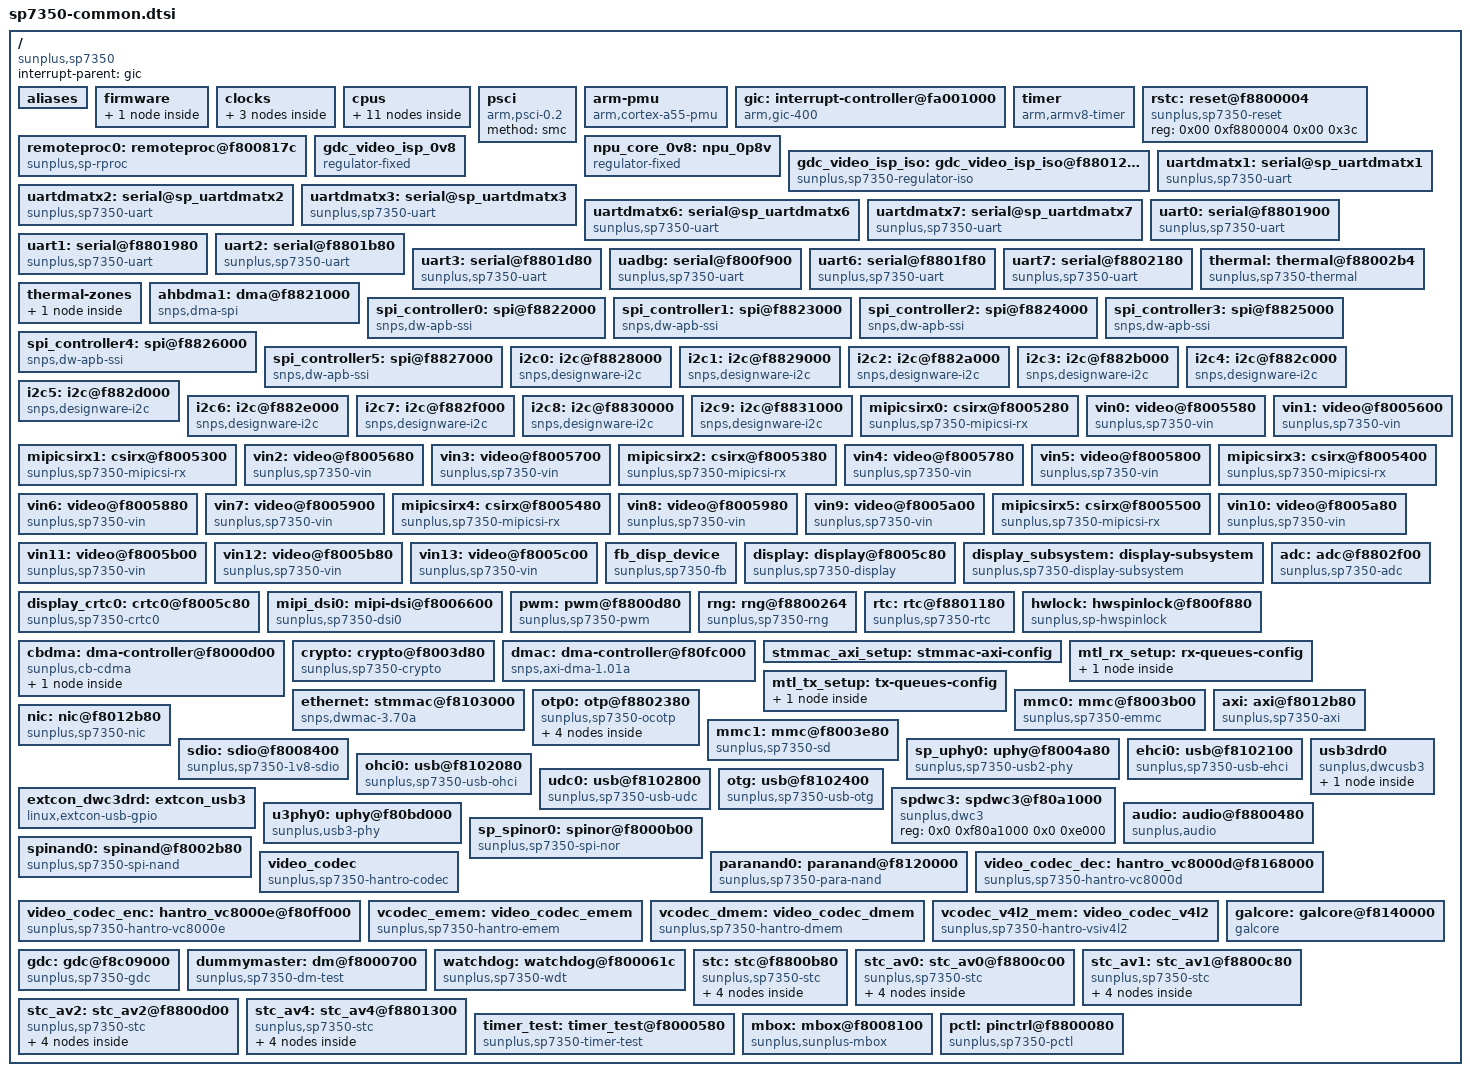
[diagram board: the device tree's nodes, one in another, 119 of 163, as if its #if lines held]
// SPDX-License-Identifier: (GPL-2.0 OR MIT)

/dts-v1/;

#include <autoconf.h>
#include <dt-bindings/interrupt-controller/irq.h>
#include <dt-bindings/interrupt-controller/arm-gic.h>
#include <dt-bindings/gpio/gpio.h>
#include <dt-bindings/clock/sp-sp7350.h>
#include <dt-bindings/reset/sp-sp7350.h>
#include <dt-bindings/pinctrl/sppctl-sp7350.h>
#include <dt-bindings/regulator/sunplus,sp7350-iso.h>

/ {
	compatible = "sunplus,sp7350";
	interrupt-parent = <&gic>;
	#address-cells = <2>;
	#size-cells = <2>;

	aliases {
#ifdef ENABLE_DMATX1
		serial21 = &uartdmatx1;
#endif
#ifdef ENABLE_DMATX2
		serial22 = &uartdmatx2;
#endif
#ifdef ENABLE_DMATX3
		serial23 = &uartdmatx3;
#endif
#ifdef ENABLE_DMATX6
		serial26 = &uartdmatx6;
#endif
#ifdef ENABLE_DMATX7
		serial27 = &uartdmatx7;
#endif
		serial0 = &uart0;
		serial1 = &uart1;
		serial2 = &uart2;
		serial3 = &uart3;
		serial5 = &uadbg;
		serial6 = &uart6;
		serial7 = &uart7;

		i2cno0 = &i2c0;
		i2cno1 = &i2c1;
		i2cno2 = &i2c2;
		i2cno3 = &i2c3;
		i2cno4 = &i2c4;
		i2cno5 = &i2c5;
		i2cno6 = &i2c6;
		i2cno7 = &i2c7;
		i2cno8 = &i2c8;
		i2cno9 = &i2c9;

		spim0 = &spi_controller0;
		spim1 = &spi_controller1;
		spim2 = &spi_controller2;
		spim3 = &spi_controller3;
		spim4 = &spi_controller4;
		spis5 = &spi_controller5;

		spi0 = &sp_spinor0;

		stc0 = &stc;
		stc1 = &stc_av0;
		stc2 = &stc_av1;
		stc3 = &stc_av2;
		stc4 = &stc_av4;

		timer0 = &stc_timer0;
		timer1 = &stc_timer1;
		timer2 = &stc_timer2;
		timer3 = &stc_timer3;
		timer4 = &stc_av0_timer0;
		timer5 = &stc_av0_timer1;
		timer6 = &stc_av0_timer2;
		timer7 = &stc_av0_timer3;
		timer8 = &stc_av1_timer0;
		timer9 = &stc_av1_timer1;
		timer10 = &stc_av1_timer2;
		timer11 = &stc_av1_timer3;
		timer12 = &stc_av2_timer0;
		timer13 = &stc_av2_timer1;
		timer14 = &stc_av2_timer2;
		timer15 = &stc_av2_timer3;
		timer16 = &stc_av4_timer0;
		timer17 = &stc_av4_timer1;
		timer18 = &stc_av4_timer2;
		timer19 = &stc_av4_timer3;
	};

	firmware {
		optee {
			compatible = "linaro,optee-tz";
			method = "smc";
		};
	};

	clocks {
		#address-cells = <2>;
		#size-cells = <2>;
		ranges;

		extclk: osc0 {
			compatible = "fixed-clock";
			#clock-cells = <0>;
			clock-frequency = <XTAL>;
			clock-output-names = "extclk";
		};

		rtcclk: rtcclk {
			compatible = "fixed-clock";
			#clock-cells = <0>;
			clock-frequency = <32000>;
			clock-output-names = "f_32k";
		};

		clkc: clkc@f8800104 {
			compatible = "sunplus,sp7350-clkc";
			reg = <0x00 0xf8800104 0x00 0x1fc>,  // MOON G2.1~G6
			      <0x00 0xf8000f00 0x00 0x080>;  // G30 QCTL
			#clock-cells = <1>;
		};
	};

	cpus {
		#address-cells = <1>;
		#size-cells = <0>;

		cpu0: cpu@0 {
			device_type = "cpu";
			compatible = "arm,cortex-a55";
			reg = <0x0000>;
			enable-method = "psci";
			clocks = <&clkc PLLC>, <&clkc PLLL3>;
			clock-names = "PLLC", "PLLL3";
			proc-supply = <&cpu_vdd_reg>;
			operating-points-v2 = <&cpu_opp_table>;
			next-level-cache = <&L2_0>;
			cpu-idle-states = <&CPU_SLEEP>;
		};

		cpu1: cpu@1 {
			device_type = "cpu";
			compatible = "arm,cortex-a55";
			reg = <0x0100>;
			enable-method = "psci";
			clocks = <&clkc PLLC>, <&clkc PLLL3>;
			clock-names = "PLLC", "PLLL3";
			proc-supply = <&cpu_vdd_reg>;
			operating-points-v2 = <&cpu_opp_table>;
			next-level-cache = <&L2_1>;
			cpu-idle-states = <&CPU_SLEEP>;
		};

		cpu2: cpu@2 {
			device_type = "cpu";
			compatible = "arm,cortex-a55";
			reg = <0x0200>;
			enable-method = "psci";
			clocks = <&clkc PLLC>, <&clkc PLLL3>;
			clock-names = "PLLC", "PLLL3";
			proc-supply = <&cpu_vdd_reg>;
			operating-points-v2 = <&cpu_opp_table>;
			next-level-cache = <&L2_2>;
			cpu-idle-states = <&CPU_SLEEP>;
		};

		cpu3: cpu@3 {
			device_type = "cpu";
			compatible = "arm,cortex-a55";
			reg = <0x0300>;
			enable-method = "psci";
			clocks = <&clkc PLLC>, <&clkc PLLL3>;
			clock-names = "PLLC", "PLLL3";
			proc-supply = <&cpu_vdd_reg>;
			operating-points-v2 = <&cpu_opp_table>;
			next-level-cache = <&L2_3>;
			cpu-idle-states = <&CPU_SLEEP>;
		};

		idle-states {
			entry-method = "psci";

			CPU_SLEEP: cpu-sleep {
				compatible = "arm,idle-state";
				local-timer-stop;
				arm,psci-suspend-param = <0x0000000>;
				entry-latency-us = <120>;
				exit-latency-us = <250>;
				min-residency-us = <900>;
			};
		};

		L2_0: l2-cache-0 {
			compatible = "cache";
			cache-level = <2>;
			next-level-cache = <&L3>;
			cache-unified;
		};

		L2_1: l2-cache-1 {
			compatible = "cache";
			cache-level = <2>;
			next-level-cache = <&L3>;
			cache-unified;
		};

		L2_2: l2-cache-2 {
			compatible = "cache";
			cache-level = <2>;
			next-level-cache = <&L3>;
			cache-unified;
		};

		L2_3: l2-cache-3 {
			compatible = "cache";
			cache-level = <2>;
			next-level-cache = <&L3>;
			cache-unified;
		};

		L3: l3-cache {
			compatible = "cache";
			cache-level = <3>;
			cache-unified;
		};
	};

	psci {
		compatible = "arm,psci-0.2";
		method = "smc";
	};

	arm-pmu {
		compatible = "arm,cortex-a55-pmu", "arm,armv8-pmuv3";
		interrupts = <GIC_SPI 475 IRQ_TYPE_LEVEL_HIGH>,
			     <GIC_SPI 476 IRQ_TYPE_LEVEL_HIGH>,
			     <GIC_SPI 477 IRQ_TYPE_LEVEL_HIGH>,
			     <GIC_SPI 478 IRQ_TYPE_LEVEL_HIGH>;
		interrupt-affinity = <&cpu0>, <&cpu1>, <&cpu2>, <&cpu3>;
	};

	gic: interrupt-controller@fa001000 {
		compatible = "arm,gic-400";
		reg = <0x00 0xfa001000 0x00 0x1000>,
		      <0x00 0xfa002000 0x00 0x2000>,
		      <0x00 0xfa004000 0x00 0x2000>,
		      <0x00 0xfa006000 0x00 0x2000>;
		#interrupt-cells = <3>;
		interrupt-controller;
	};

	timer {
		compatible = "arm,armv8-timer";
		interrupt-parent = <&gic>;
		clock-frequency = <XTAL>;
		interrupts = <GIC_PPI 13 (GIC_CPU_MASK_RAW(15) | IRQ_TYPE_LEVEL_LOW)>,
			     <GIC_PPI 14 (GIC_CPU_MASK_RAW(15) | IRQ_TYPE_LEVEL_LOW)>,
			     <GIC_PPI 11 (GIC_CPU_MASK_RAW(15) | IRQ_TYPE_LEVEL_LOW)>,
			     <GIC_PPI 10 (GIC_CPU_MASK_RAW(15) | IRQ_TYPE_LEVEL_LOW)>;
	};

	rstc: reset@f8800004 {
		compatible = "sunplus,sp7350-reset";
		reg = <0x00 0xf8800004 0x00 0x3c>;
		reg-names = "reset";
		#reset-cells = <1>;
	};

	remoteproc0: remoteproc@f800817c {
		compatible = "sunplus,sp-rproc";
		reg = <0 0xf800817c 0 4>, /* mbox G258.31, cpu0 to cpu2 direct reg07 */
		      <0 0xf8800250 0 4>,
		      <0 0xf80081fc 0 4>; /* mbox G259.31, cpu2 to cpu0 direct reg07 */
		interrupt-parent = <&gic>;
		interrupts = <GIC_SPI 125 IRQ_TYPE_LEVEL_HIGH>; /* CPU2_TO_0_DIRECT_INT7 */
		resets = <&rstc RST_CM4>;
#ifdef CONFIG_SUNPLUS_MBOX_TEST
		mboxes = <&mbox 0>;
#endif
	};

	npu_core_0v8: npu_0p8v {
		compatible = "regulator-fixed";
		regulator-name = "npu_core";
		regulator-min-microvolt = <800000>;
		regulator-max-microvolt = <800000>;
	};

	gdc_video_isp_0v8: gdc_video_isp_0v8 {
		compatible = "regulator-fixed";
		regulator-name = "video_codec_core";
		regulator-min-microvolt = <800000>;
		regulator-max-microvolt = <800000>;
	};

	gdc_video_isp_iso: gdc_video_isp_iso@f880125c {
		compatible = "sunplus,sp7350-regulator-iso";
		reg = <0x00 0xf880125c 0x00 0x4>;
		regulator-name = "sp7350-iso";
		sunplus,iso-selector = <SP7350_ISO_VIDEO>;
	};

#ifdef ENABLE_DMATX1
	uartdmatx1: serial@sp_uartdmatx1 {
		compatible = "sunplus,sp7350-uart";
		reg = <0x00 0xf8801b40 0x00 0x40>, <0x00 0xf8801a80 0x00 0x80>;
		//clocks = <&clkc GDMAUA>;
		which-uart = <1>;
	};
#endif

#ifdef ENABLE_DMATX2
	uartdmatx2: serial@sp_uartdmatx2 {
		compatible = "sunplus,sp7350-uart";
		reg = <0x00 0xf8801d40 0x00 0x40>, <0x00 0xf8801c80 0x00 0x80>;
		//clocks = <&clkc GDMAUA>;
		which-uart = <2>;
	};
#endif

#ifdef ENABLE_DMATX3
	uartdmatx3: serial@sp_uartdmatx3 {
		compatible = "sunplus,sp7350-uart";
		reg = <0x00 0xf8801f40 0x00 0x40>, <0x00 0xf8801e80 0x00 0x80>;
		//clocks = <&clkc GDMAUA>;
		which-uart = <3>;
	};
#endif

#ifdef ENABLE_DMATX6
	uartdmatx6: serial@sp_uartdmatx6 {
		compatible = "sunplus,sp7350-uart";
		reg = <0x00 0xf8802140 0x00 0x40>, <0x00 0xf8802080 0x00 0x80>;
		//clocks = <&clkc GDMAUA>;
		which-uart = <6>;
	};
#endif

#ifdef ENABLE_DMATX7
	uartdmatx7: serial@sp_uartdmatx7 {
		compatible = "sunplus,sp7350-uart";
		reg = <0x00 0xf8802340 0x00 0x40>, <0x00 0xf8802280 0x00 0x80>;
		//clocks = <&clkc GDMAUA>;
		which-uart = <7>;
	};
#endif

	uart0: serial@f8801900 {
		compatible = "sunplus,sp7350-uart";
		reg = <0x00 0xf8801900 0x00 0x80>;
		interrupt-parent = <&gic>;
		interrupts = <GIC_SPI 60 IRQ_TYPE_LEVEL_HIGH>;
		clocks = <&clkc UA0>;
		resets = <&rstc RST_UA0>;
	};

	uart1: serial@f8801980 {
		compatible = "sunplus,sp7350-uart";
		reg = <0x00 0xf8801980 0x00 0x80>;
		interrupt-parent = <&gic>;
		interrupts = <GIC_SPI 61 IRQ_TYPE_LEVEL_HIGH>;
		clocks = <&clkc UA1>;
		resets = <&rstc RST_UA1>;
	};

	uart2: serial@f8801b80 {
		compatible = "sunplus,sp7350-uart";
		reg = <0x00 0xf8801b80 0x00 0x80>;
		interrupt-parent = <&gic>;
		interrupts = <GIC_SPI 157 IRQ_TYPE_LEVEL_HIGH>;
		clocks = <&clkc UA2>;
		resets = <&rstc RST_UA2>;
	};

	uart3: serial@f8801d80 {
		compatible = "sunplus,sp7350-uart";
		reg = <0x00 0xf8801d80 0x00 0x80>;
		interrupt-parent = <&gic>;
		interrupts = <GIC_SPI 158 IRQ_TYPE_LEVEL_HIGH>;
		clocks = <&clkc UA3>;
		resets = <&rstc RST_UA3>;
	};

	uadbg: serial@f800f900 {
		compatible = "sunplus,sp7350-uart";
		reg = <0x00 0xf800f900 0x00 0x80>;
		interrupt-parent = <&gic>;
		interrupts = <GIC_SPI 35 IRQ_TYPE_LEVEL_HIGH>;
		clocks = <&clkc UADBG>;
		resets = <&rstc RST_UADBG>;
	};

	uart6: serial@f8801f80 {
		compatible = "sunplus,sp7350-uart";
		reg = <0x00 0xf8801f80 0x00 0x80>;
		interrupt-parent = <&gic>;
		interrupts = <GIC_SPI 162 IRQ_TYPE_LEVEL_HIGH>;
		clocks = <&clkc UA6>;
		resets = <&rstc RST_UA6>;
	};

	uart7: serial@f8802180 {
		compatible = "sunplus,sp7350-uart";
		reg = <0x00 0xf8802180 0x00 0x80>;
		interrupt-parent = <&gic>;
		interrupts = <GIC_SPI 159 IRQ_TYPE_LEVEL_HIGH>;
		clocks = <&clkc UA7>;
		resets = <&rstc RST_UA7>;
	};

	thermal: thermal@f88002b4 {
		compatible = "sunplus,sp7350-thermal";
		reg =<0x0 0xf88002b4 0x0 0x18>;
		clocks = <&clkc THERMAL>;
		resets = <&rstc RST_THERMAL>;
		#thermal-sensor-cells = <0>;
		nvmem-cell-names = "therm_calib";
		nvmem-cells = <&therm_calib>;
	};

	thermal-zones {
		cpu_thermal_zone: cpu-thermal {
			thermal-sensors = <&thermal 0>;
		};
	};

	ahbdma1: dma@f8821000 {
		compatible = "snps,dma-spi";
		reg =<0x0 0xf8821000 0x0 0x400>;
		interrupt-parent = <&gic>;
		interrupts = <GIC_SPI 178 IRQ_TYPE_EDGE_RISING>,
			     <GIC_SPI 180 IRQ_TYPE_EDGE_RISING>,
			     <GIC_SPI 192 IRQ_TYPE_EDGE_RISING>,
			     <GIC_SPI 193 IRQ_TYPE_EDGE_RISING>,
			     <GIC_SPI 194 IRQ_TYPE_EDGE_RISING>,
			     <GIC_SPI 195 IRQ_TYPE_EDGE_RISING>,
			     <GIC_SPI 196 IRQ_TYPE_EDGE_RISING>,
			     <GIC_SPI 199 IRQ_TYPE_EDGE_RISING>;
		dma-channels = <8>;
		#dma-cells = <3>;
	};

	spi_controller0: spi@f8822000 {
		compatible = "snps,dw-apb-ssi";
		reg =<0x0 0xf8822000 0x0 0x100>;
		#address-cells = <1>;
		#size-cells = <0>;
		interrupt-parent = <&gic>;
		interrupts = <GIC_SPI 27 IRQ_TYPE_LEVEL_HIGH>;
		clocks = <&clkc SPICB0>;
		resets = <&rstc RST_SPICB0>;
	};

	spi_controller1: spi@f8823000 {
		compatible = "snps,dw-apb-ssi";
		reg =<0x0 0xf8823000 0x0 0x100>;
		#address-cells = <1>;
		#size-cells = <0>;
		interrupt-parent = <&gic>;
		interrupts = <GIC_SPI 28 IRQ_TYPE_LEVEL_HIGH>;
		clocks = <&clkc SPICB1>;
		resets = <&rstc RST_SPICB1>;
	};

	spi_controller2: spi@f8824000 {
		compatible = "snps,dw-apb-ssi";
		reg =<0x0 0xf8824000 0x0 0x100>;
		#address-cells = <1>;
		#size-cells = <0>;
		interrupt-parent = <&gic>;
		interrupts = <GIC_SPI 29 IRQ_TYPE_LEVEL_HIGH>;
		clocks = <&clkc SPICB2>;
		resets = <&rstc RST_SPICB2>;
	};

	spi_controller3: spi@f8825000 {
		compatible = "snps,dw-apb-ssi";
		reg =<0x0 0xf8825000 0x0 0x100>;
		#address-cells = <1>;
		#size-cells = <0>;
		interrupt-parent = <&gic>;
		interrupts = <GIC_SPI 30 IRQ_TYPE_LEVEL_HIGH>;
		clocks = <&clkc SPICB3>;
		resets = <&rstc RST_SPICB3>;
	};

	spi_controller4: spi@f8826000 {
		compatible = "snps,dw-apb-ssi";
		reg =<0x0 0xf8826000 0x0 0x100>;
		#address-cells = <1>;
		#size-cells = <0>;
		interrupt-parent = <&gic>;
		interrupts = <GIC_SPI 31 IRQ_TYPE_LEVEL_HIGH>;
		clocks = <&clkc SPICB4>;
		resets = <&rstc RST_SPICB4>;
	};

	spi_controller5: spi@f8827000 {
		compatible = "snps,dw-apb-ssi";
		reg =<0x0 0xf8827000 0x0 0x100>;
		#address-cells = <1>;
		#size-cells = <0>;
		interrupt-parent = <&gic>;
		interrupts = <GIC_SPI 32 IRQ_TYPE_LEVEL_HIGH>;
		clocks = <&clkc SPICB5>;
		resets = <&rstc RST_SPICB5>;
	};

	i2c0: i2c@f8828000 {
		compatible = "snps,designware-i2c";
		reg =<0x0 0xf8828000 0x0 0x100>;
		interrupt-parent = <&gic>;
		interrupts = <GIC_SPI 8 IRQ_TYPE_LEVEL_HIGH>;
		clocks = <&clkc I2CM0>;
		resets = <&rstc RST_I2CM0>;
	};

	i2c1: i2c@f8829000 {
		compatible = "snps,designware-i2c";
		reg =<0x0 0xf8829000 0x0 0x100>;
		interrupt-parent = <&gic>;
		interrupts = <GIC_SPI 94 IRQ_TYPE_LEVEL_HIGH>;
		clocks = <&clkc I2CM1>;
		resets = <&rstc RST_I2CM1>;
	};

	i2c2: i2c@f882a000 {
		compatible = "snps,designware-i2c";
		reg =<0x0 0xf882a000 0x0 0x100>;
		interrupt-parent = <&gic>;
		interrupts = <GIC_SPI 95 IRQ_TYPE_LEVEL_HIGH>;
		clocks = <&clkc I2CM2>;
		resets = <&rstc RST_I2CM2>;
	};

	i2c3: i2c@f882b000 {
		compatible = "snps,designware-i2c";
		reg =<0x0 0xf882b000 0x0 0x100>;
		interrupt-parent = <&gic>;
		interrupts = <GIC_SPI 96 IRQ_TYPE_LEVEL_HIGH>;
		clocks = <&clkc I2CM3>;
		resets = <&rstc RST_I2CM3>;
	};

	i2c4: i2c@f882c000 {
		compatible = "snps,designware-i2c";
		reg =<0x0 0xf882c000 0x0 0x100>;
		interrupt-parent = <&gic>;
		interrupts = <GIC_SPI 97 IRQ_TYPE_LEVEL_HIGH>;
		clocks = <&clkc I2CM4>;
		resets = <&rstc RST_I2CM4>;
	};

	i2c5: i2c@f882d000 {
		compatible = "snps,designware-i2c";
		reg =<0x0 0xf882d000 0x0 0x100>;
		interrupt-parent = <&gic>;
		interrupts = <GIC_SPI 98 IRQ_TYPE_LEVEL_HIGH>;
		clocks = <&clkc I2CM5>;
		resets = <&rstc RST_I2CM5>;
	};

	i2c6: i2c@f882e000 {
		compatible = "snps,designware-i2c";
		reg =<0x0 0xf882e000 0x0 0x100>;
		interrupt-parent = <&gic>;
		interrupts = <GIC_SPI 22 IRQ_TYPE_LEVEL_HIGH>;
		clocks = <&clkc I2CM6>;
		resets = <&rstc RST_I2CM6>;
	};

	i2c7: i2c@f882f000 {
		compatible = "snps,designware-i2c";
		reg =<0x0 0xf882f000 0x0 0x100>;
		interrupt-parent = <&gic>;
		interrupts = <GIC_SPI 110 IRQ_TYPE_LEVEL_HIGH>;
		clocks = <&clkc I2CM7>;
		resets = <&rstc RST_I2CM7>;
	};

	i2c8: i2c@f8830000 {
		compatible = "snps,designware-i2c";
		reg =<0x0 0xf8830000 0x0 0x100>;
		interrupt-parent = <&gic>;
		interrupts = <GIC_SPI 111 IRQ_TYPE_LEVEL_HIGH>;
		clocks = <&clkc I2CM8>;
		resets = <&rstc RST_I2CM8>;
	};

	i2c9: i2c@f8831000 {
		compatible = "snps,designware-i2c";
		reg =<0x0 0xf8831000 0x0 0x100>;
		interrupt-parent = <&gic>;
		interrupts = <GIC_SPI 169 IRQ_TYPE_LEVEL_HIGH>;
		clocks = <&clkc I2CM9>;
		resets = <&rstc RST_I2CM9>;
	};

	mipicsirx0: csirx@f8005280 {
		compatible = "sunplus,sp7350-mipicsi-rx";
		reg = <0x0 0xf8005280 0x0 0x80>;
		reg-names = "mipicsi";
		clocks = <&clkc MIPICSI0>;
		clock-names = "clk_mipicsi";
		resets = <&rstc RST_MIPICSI0>;
		reset-names = "rstc_mipicsi";
		sunplus,id = <0>;
	};

	vin0: video@f8005580 {
		compatible = "sunplus,sp7350-vin";
		reg = <0x0 0xf8005580 0x0 0x80>;
		reg-names = "csiiw";
		interrupt-parent = <&gic>;
		interrupts = <GIC_SPI 36 IRQ_TYPE_LEVEL_HIGH>,
			     <GIC_SPI 37 IRQ_TYPE_LEVEL_HIGH>;
		interrupt-names = "fs_irq", "fe_irq";
		clocks = <&clkc VI0_CSIIW0>;
		clock-names = "clk_csiiw";
		resets = <&rstc RST_VI0_CSIIW0>;
		reset-names = "rstc_csiiw";
		sunplus,id = <0>;
	};

	vin1: video@f8005600 {
		compatible = "sunplus,sp7350-vin";
		reg = <0x0 0xf8005600 0x0 0x80>;
		reg-names = "csiiw";
		interrupt-parent = <&gic>;
		interrupts = <GIC_SPI 38 IRQ_TYPE_LEVEL_HIGH>,
			     <GIC_SPI 39 IRQ_TYPE_LEVEL_HIGH>;
		interrupt-names = "fs_irq", "fe_irq";
		clocks = <&clkc VI0_CSIIW1>;
		clock-names = "clk_csiiw";
		resets = <&rstc RST_VI0_CSIIW1>;
		reset-names = "rstc_csiiw";
		sunplus,id = <1>;
	};

	mipicsirx1: csirx@f8005300 {
		compatible = "sunplus,sp7350-mipicsi-rx";
		reg = <0x0 0xf8005300 0x0 0x80>;
		reg-names = "mipicsi";
		clocks = <&clkc MIPICSI1>;
		clock-names = "clk_mipicsi";
		resets = <&rstc RST_MIPICSI1>;
		reset-names = "rstc_mipicsi";
		sunplus,id = <1>;
	};

	vin2: video@f8005680 {
		compatible = "sunplus,sp7350-vin";
		reg = <0x0 0xf8005680 0x0 0x80>;
		reg-names = "csiiw";
		interrupt-parent = <&gic>;
		interrupts = <GIC_SPI 40 IRQ_TYPE_LEVEL_HIGH>,
			     <GIC_SPI 41 IRQ_TYPE_LEVEL_HIGH>;
		interrupt-names = "fs_irq", "fe_irq";
		clocks = <&clkc VI1_CSIIW0>;
		clock-names = "clk_csiiw";
		resets = <&rstc RST_VI1_CSIIW0>;
		reset-names = "rstc_csiiw";
		sunplus,id = <2>;
	};

	vin3: video@f8005700 {
		compatible = "sunplus,sp7350-vin";
		reg = <0x0 0xf8005700 0x0 0x80>;
		reg-names = "csiiw";
		interrupt-parent = <&gic>;
		interrupts = <GIC_SPI 42 IRQ_TYPE_LEVEL_HIGH>,
			     <GIC_SPI 43 IRQ_TYPE_LEVEL_HIGH>;
		interrupt-names = "fs_irq", "fe_irq";
		clocks = <&clkc VI1_CSIIW1>;
		clock-names = "clk_csiiw";
		resets = <&rstc RST_VI1_CSIIW1>;
		reset-names = "rstc_csiiw";
		sunplus,id = <3>;
	};

	mipicsirx2: csirx@f8005380 {
		compatible = "sunplus,sp7350-mipicsi-rx";
		reg = <0x0 0xf8005380 0x0 0x80>, <0x0 0xf8005200 0x0 0x80>;
		reg-names = "mipicsi", "mipicsi23sel";
		clocks = <&clkc MIPICSI2>, <&clkc MIPICSI23_SEL>;
		clock-names = "clk_mipicsi", "clk_mipicsi23_sel";
		resets = <&rstc RST_MIPICSI2>;
		reset-names = "rstc_mipicsi";
		sunplus,id = <2>;
	};

	vin4: video@f8005780 {
		compatible = "sunplus,sp7350-vin";
		reg = <0x0 0xf8005780 0x0 0x80>;
		reg-names = "csiiw";
		interrupt-parent = <&gic>;
		interrupts = <GIC_SPI 80 IRQ_TYPE_LEVEL_HIGH>,
			     <GIC_SPI 81 IRQ_TYPE_LEVEL_HIGH>;
		interrupt-names = "fs_irq", "fe_irq";
		clocks = <&clkc VI23_CSIIW0>;
		clock-names = "clk_csiiw";
		resets = <&rstc RST_VI23_CSIIW0>;
		reset-names = "rstc_csiiw";
		sunplus,id = <4>;
	};

	vin5: video@f8005800 {
		compatible = "sunplus,sp7350-vin";
		reg = <0x0 0xf8005800 0x0 0x80>;
		reg-names = "csiiw";
		interrupt-parent = <&gic>;
		interrupts = <GIC_SPI 82 IRQ_TYPE_LEVEL_HIGH>,
			     <GIC_SPI 83 IRQ_TYPE_LEVEL_HIGH>;
		interrupt-names = "fs_irq", "fe_irq";
		clocks = <&clkc VI23_CSIIW1>;
		clock-names = "clk_csiiw";
		resets = <&rstc RST_VI23_CSIIW1>;
		reset-names = "rstc_csiiw";
		sunplus,id = <5>;
	};

#ifndef MIPI_CSI_4VC
	mipicsirx3: csirx@f8005400 {
		compatible = "sunplus,sp7350-mipicsi-rx";
		reg = <0x0 0xf8005400 0x0 0x80>, <0x0 0xf8005200 0x0 0x80>;
		reg-names = "mipicsi", "mipicsi23sel";
		clocks = <&clkc MIPICSI3>, <&clkc MIPICSI23_SEL>;
		clock-names = "clk_mipicsi", "clk_mipicsi23_sel";
		resets = <&rstc RST_MIPICSI3>;
		reset-names = "rstc_mipicsi";
		sunplus,id = <3>;
	};
#endif

	vin6: video@f8005880 {
		compatible = "sunplus,sp7350-vin";
		reg = <0x0 0xf8005880 0x0 0x80>;
		reg-names = "csiiw";
		interrupt-parent = <&gic>;
		interrupts = <GIC_SPI 84 IRQ_TYPE_LEVEL_HIGH>,
			     <GIC_SPI 85 IRQ_TYPE_LEVEL_HIGH>;
		interrupt-names = "fs_irq", "fe_irq";
		clocks = <&clkc VI23_CSIIW2>;
		clock-names = "clk_csiiw";
		resets = <&rstc RST_VI23_CSIIW2>;
		reset-names = "rstc_csiiw";
		sunplus,id = <6>;
	};

	vin7: video@f8005900 {
		compatible = "sunplus,sp7350-vin";
		reg = <0x0 0xf8005900 0x0 0x80>;
		reg-names = "csiiw";
		interrupt-parent = <&gic>;
		interrupts = <GIC_SPI 86 IRQ_TYPE_LEVEL_HIGH>,
			     <GIC_SPI 87 IRQ_TYPE_LEVEL_HIGH>;
		interrupt-names = "fs_irq", "fe_irq";
		clocks = <&clkc VI23_CSIIW3>;
		clock-names = "clk_csiiw";
		resets = <&rstc RST_VI23_CSIIW3>;
		reset-names = "rstc_csiiw";
		sunplus,id = <7>;
	};

	mipicsirx4: csirx@f8005480 {
		compatible = "sunplus,sp7350-mipicsi-rx";
		reg = <0x0 0xf8005480 0x0 0x80>;
		reg-names = "mipicsi";
		clocks = <&clkc MIPICSI4>;
		clock-names = "clk_mipicsi";
		resets = <&rstc RST_MIPICSI4>;
		reset-names = "rstc_mipicsi";
		sunplus,id = <4>;
	};

	vin8: video@f8005980 {
		compatible = "sunplus,sp7350-vin";
		reg = <0x0 0xf8005980 0x0 0x80>;
		reg-names = "csiiw";
		interrupt-parent = <&gic>;
		interrupts = <GIC_SPI 44 IRQ_TYPE_LEVEL_HIGH>,
			     <GIC_SPI 45 IRQ_TYPE_LEVEL_HIGH>;
		interrupt-names = "fs_irq", "fe_irq";
		clocks = <&clkc VI4_CSIIW0>;
		clock-names = "clk_csiiw";
		resets = <&rstc RST_VI4_CSIIW0>;
		reset-names = "rstc_csiiw";
		sunplus,id = <8>;
	};

	vin9: video@f8005a00 {
		compatible = "sunplus,sp7350-vin";
		reg = <0x0 0xf8005a00 0x0 0x80>;
		reg-names = "csiiw";
		interrupt-parent = <&gic>;
		interrupts = <GIC_SPI 46 IRQ_TYPE_LEVEL_HIGH>,
			     <GIC_SPI 47 IRQ_TYPE_LEVEL_HIGH>;
		interrupt-names = "fs_irq", "fe_irq";
		clocks = <&clkc VI4_CSIIW1>;
		clock-names = "clk_csiiw";
		resets = <&rstc RST_VI4_CSIIW1>;
		reset-names = "rstc_csiiw";
		sunplus,id = <9>;
	};

	mipicsirx5: csirx@f8005500 {
		compatible = "sunplus,sp7350-mipicsi-rx";
		reg = <0x0 0xf8005500 0x0 0x80>;
		reg-names = "mipicsi";
		clocks = <&clkc MIPICSI5>;
		clock-names = "clk_mipicsi";
		resets = <&rstc RST_MIPICSI5>;
		reset-names = "rstc_mipicsi";
		sunplus,id = <5>;
	};

	vin10: video@f8005a80 {
		compatible = "sunplus,sp7350-vin";
		reg = <0x0 0xf8005a80 0x0 0x80>;
		reg-names = "csiiw";
		interrupt-parent = <&gic>;
		interrupts = <GIC_SPI 170 IRQ_TYPE_LEVEL_HIGH>,
			     <GIC_SPI 171 IRQ_TYPE_LEVEL_HIGH>;
		interrupt-names = "fs_irq", "fe_irq";
		clocks = <&clkc VI5_CSIIW0>;
		clock-names = "clk_csiiw";
		resets = <&rstc RST_VI5_CSIIW0>;
		reset-names = "rstc_csiiw";
		sunplus,id = <10>;
	};

	vin11: video@f8005b00 {
		compatible = "sunplus,sp7350-vin";
		reg = <0x0 0xf8005b00 0x0 0x80>;
		reg-names = "csiiw";
		interrupt-parent = <&gic>;
		interrupts = <GIC_SPI 172 IRQ_TYPE_LEVEL_HIGH>,
			     <GIC_SPI 173 IRQ_TYPE_LEVEL_HIGH>;
		interrupt-names = "fs_irq", "fe_irq";
		clocks = <&clkc VI5_CSIIW1>;
		clock-names = "clk_csiiw";
		resets = <&rstc RST_VI5_CSIIW1>;
		reset-names = "rstc_csiiw";
		sunplus,id = <11>;
	};

	vin12: video@f8005b80 {
		compatible = "sunplus,sp7350-vin";
		reg = <0x0 0xf8005b80 0x0 0x80>;
		reg-names = "csiiw";
		interrupt-parent = <&gic>;
		interrupts = <GIC_SPI 174 IRQ_TYPE_LEVEL_HIGH>,
			     <GIC_SPI 175 IRQ_TYPE_LEVEL_HIGH>;
		interrupt-names = "fs_irq", "fe_irq";
		clocks = <&clkc VI5_CSIIW2>;
		clock-names = "clk_csiiw";
		resets = <&rstc RST_VI5_CSIIW2>;
		reset-names = "rstc_csiiw";
		sunplus,id = <12>;
	};

	vin13: video@f8005c00 {
		compatible = "sunplus,sp7350-vin";
		reg = <0x0 0xf8005c00 0x0 0x80>;
		reg-names = "csiiw";
		interrupt-parent = <&gic>;
		interrupts = <GIC_SPI 176 IRQ_TYPE_LEVEL_HIGH>,
			     <GIC_SPI 177 IRQ_TYPE_LEVEL_HIGH>;
		interrupt-names = "fs_irq", "fe_irq";
		clocks = <&clkc VI5_CSIIW3>;
		clock-names = "clk_csiiw";
		resets = <&rstc RST_VI5_CSIIW3>;
		reset-names = "rstc_csiiw";
		sunplus,id = <13>;
	};

	fb_disp_device: fb_disp_device {
		compatible = "sunplus,sp7350-fb";
	};

	display: display@f8005c80 {
		compatible = "sunplus,sp7350-display";
		reg = <0x00 0xf8005c80 0x00 0xa80>, <0x00 0xf8800180 0x00 0x80>;
		interrupt-parent = <&gic>;
		interrupts =
			<GIC_SPI 104 IRQ_TYPE_LEVEL_HIGH>, <GIC_SPI 105 IRQ_TYPE_LEVEL_HIGH>,
			<GIC_SPI 106 IRQ_TYPE_LEVEL_HIGH>, <GIC_SPI 107 IRQ_TYPE_LEVEL_HIGH>;
		clocks =
			<&clkc DISPSYS>, <&clkc DMIX>, <&clkc GPOST0>, <&clkc GPOST1>,
			<&clkc GPOST2>, <&clkc GPOST3>, <&clkc IMGREAD0>, <&clkc MIPITX>,
			<&clkc OSD0>, <&clkc OSD1>, <&clkc OSD2>, <&clkc OSD3>,
			<&clkc TCON>, <&clkc TGEN>, <&clkc VPOST0>, <&clkc VSCL0>;
		clock-names =
			"clkc_dispsys", "clkc_dmix", "clkc_gpost0", "clkc_gpost1",
			"clkc_gpost2", "clkc_gpost3", "clkc_imgread0", "clkc_mipitx",
			"clkc_osd0", "clkc_osd1", "clkc_osd2", "clkc_osd3",
			"clkc_tcon", "clkc_tgen", "clkc_vpost0", "clkc_vscl0";
		resets =
			<&rstc RST_DISPSYS>, <&rstc RST_DMIX>, <&rstc RST_GPOST0>, <&rstc RST_GPOST1>,
			<&rstc RST_GPOST2>, <&rstc RST_GPOST3>, <&rstc RST_IMGREAD0>, <&rstc RST_MIPITX>,
			<&rstc RST_OSD0>, <&rstc RST_OSD1>, <&rstc RST_OSD2>, <&rstc RST_OSD3>,
			<&rstc RST_TCON>, <&rstc RST_TGEN>, <&rstc RST_VPOST0>, <&rstc RST_VSCL0>;
		reset-names =
			"rstc_dispsys", "rstc_dmix", "rstc_gpost0", "rstc_gpost1",
			"rstc_gpost2", "rstc_gpost3", "rstc_imgread0", "rstc_mipitx",
			"rstc_osd0", "rstc_osd1", "rstc_osd2", "rstc_osd3",
			"rstc_tcon", "rstc_tgen", "rstc_vpost0", "rstc_vscl0";
	};

	display_subsystem: display-subsystem {
		compatible = "sunplus,sp7350-display-subsystem";
	};

	display_crtc0: crtc0@f8005c80 {
		compatible = "sunplus,sp7350-crtc0";
		reg = <0x00 0xf8005c80 0x00 0x980>;

		interrupt-parent = <&gic>;
		interrupts =
			<GIC_SPI 104 IRQ_TYPE_LEVEL_HIGH>;
	};

	mipi_dsi0: mipi-dsi@f8006600 {
		compatible = "sunplus,sp7350-dsi0";

		reg = <0x00 0xf8006600 0x00 0xb8>, <0x00 0xf8800180 0x00 0x80>;

		clocks =
			<&clkc DISPSYS>, <&clkc DMIX>, <&clkc TGEN>, <&clkc TCON>, <&clkc MIPITX>,
			<&clkc GPOST0>, <&clkc GPOST1>, <&clkc GPOST2>, <&clkc GPOST3>,
			<&clkc OSD0>, <&clkc OSD1>, <&clkc OSD2>, <&clkc OSD3>,
			<&clkc IMGREAD0>, <&clkc VSCL0>, <&clkc VPOST0>;
		clock-names =
			"clkc_dispsys", "clkc_dmix", "clkc_tgen", "clkc_tcon", "clkc_mipitx",
			"clkc_gpost0", "clkc_gpost1", "clkc_gpost2", "clkc_gpost3",
			"clkc_osd0", "clkc_osd1", "clkc_osd2", "clkc_osd3",
			"clkc_imgread0", "clkc_vscl0", "clkc_vpost0";
		resets =
			<&rstc RST_DISPSYS>, <&rstc RST_DMIX>, <&rstc RST_TGEN>, <&rstc RST_TCON>, <&rstc RST_MIPITX>,
			<&rstc RST_GPOST0>, <&rstc RST_GPOST1>, <&rstc RST_GPOST2>, <&rstc RST_GPOST3>,
			<&rstc RST_OSD0>, <&rstc RST_OSD1>, <&rstc RST_OSD2>, <&rstc RST_OSD3>,
			<&rstc RST_IMGREAD0>, <&rstc RST_VSCL0>, <&rstc RST_VPOST0>;
		reset-names =
			"rstc_dispsys", "rstc_dmix", "rstc_tgen", "rstc_tcon", "rstc_mipitx",
			"rstc_gpost0", "rstc_gpost1", "rstc_gpost2", "rstc_gpost3",
			"rstc_osd0", "rstc_osd1", "rstc_osd2", "rstc_osd3",
			"rstc_imgread0", "rstc_vscl0", "rstc_vpost0";
	};

	adc: adc@f8802f00 {
		compatible = "sunplus,sp7350-adc";
		reg = <0x0 0xf8802f00 0x0 0x80>;
		clocks = <&clkc SAR12B>;
		resets = <&rstc RST_SAR12B>;
		#io-channel-cells = <1>;
		hwlocks = <&hwlock 1>;
	};

	pwm: pwm@f8800d80 {
		#pwm-cells = <2>;
		compatible = "sunplus,sp7350-pwm";
		reg = <0x0 0xf8800d80 0x0 0x100>;
		clocks = <&clkc DISP_PWM>;
		resets = <&rstc RST_DISP_PWM>;
	};

	rng: rng@f8800264 {
		compatible = "sunplus,sp7350-rng";
		reg = <0x0 0xf8800264 0x0 0x08>;
		clocks = <&clkc PRNG>;
		resets = <&rstc RST_PRNG>;
	};

	rtc: rtc@f8801180 {
		compatible = "sunplus,sp7350-rtc";
		reg = <0x0 0xf8801180 0x0 0x30>,
			  <0x0 0xf8008178 0x0 0x04>; /* mbox G258.30, cpu0 to cpu2 direct reg06 */
		reg-names = "rtc_reg","mbox_reg";
		clocks = <&clkc RTC>;
		resets = <&rstc RST_RTC>;
		interrupt-parent = <&gic>;
		interrupts = <GIC_SPI 141 IRQ_TYPE_EDGE_RISING>;
	};

	hwlock: hwspinlock@f800f880 {
		compatible = "sunplus,sp-hwspinlock";
		#hwlock-cells = <1>;
		reg = <0 0xf800f880 0 0x80>;
		clocks = <&clkc SEMAPHORE>;
		clock-names = "hsem";
	};

	cbdma: dma-controller@f8000d00 {
		compatible = "sunplus,cb-cdma";
		reg = <0x0 0xf8000d00 0x0 0x80>;
		reg-names = "cb_dma";
		clocks = <&clkc CBDMA0>;
		resets = <&rstc RST_CBDMA0>;
		interrupt-parent = <&gic>;
		interrupts = <GIC_SPI 74 IRQ_TYPE_LEVEL_HIGH>;
		sunplus,addrwidth = <0x20>;
		#dma-cells = <1>;

		dma-channel-0 {
			compatible = "sunplus,cb-cdma-channel";
			interrupts = <GIC_SPI 74 IRQ_TYPE_LEVEL_HIGH>;
			datawidth = <0x20>;
		};
	};

	crypto: crypto@f8003d80 {
		compatible = "sunplus,sp7350-crypto";
		reg = <0x0 0xf8003d80 0x0 0x100>; /* G123 ~ G124 */
		clocks = <&clkc SEC>;
		resets = <&rstc RST_SEC>;
		interrupt-parent = <&gic>;
		interrupts = <GIC_SPI 48 IRQ_TYPE_LEVEL_HIGH>;
	};

	dmac: dma-controller@f80fc000 {
		compatible = "snps,axi-dma-1.01a";
		reg = <0x00 0xf80fc000 0x00 0x10a0>;
		clocks = <&clkc AXI_DMA>;
		clock-names = "core-clk";
		resets = <&rstc RST_AXI_DMA>;
		reset-names = "core-rstc";
		interrupt-parent = <&gic>;
		interrupts = <GIC_SPI 20 IRQ_TYPE_LEVEL_HIGH>;
		#dma-cells = <1>;
		dma-channels = <16>;
	};

	stmmac_axi_setup: stmmac-axi-config {
		/*LPI switch*/
		snps,lpi_en;
		snps,xit_frm;
		snps,wr_osr_lmt = <0xf>;
		snps,rd_osr_lmt = <0xf>;
		snps,blen = <256 128 64 32 0 0 0>;
		//snps,axi_fb;
		snps,axi_mb;
	};

	mtl_rx_setup: rx-queues-config {
		snps,rx-queues-to-use = <1>;
		snps,rx-sched-sp;
		//snps,rx-sched-wsp;
		queue0 {
			snps,dcb-algorithm;
			//snps,avb-algorithm;
			snps,map-to-dma-channel = <0x0>;
			snps,priority = <0x0>;
		};
	};

	mtl_tx_setup: tx-queues-config {
		snps,tx-queues-to-use = <1>;
		/*use will cause dev_watchdog() function panic*/
		//snps,tx-sched-wrr;
		//snps,tx-sched-wfq;
		//snps,tx-sched-dwrr;
		snps,tx-sched-sp;
		queue0 {
			/*use will cause dev_watchdog() function panic*/
			//snps,weight = <0x10>;
			snps,dcb-algorithm;
			snps,map-to-dma-channel = <0x0>;
			snps,priority = <0x0>;
		};
		/*use will cause dev_watchdog() function panic*/
		//queue1 {
		//	snps,avb-algorithm;
		//	snps,send_slope = <0x1000>;
		//	snps,idle_slope = <0x2000>;
		//	snps,high_credit = <0x3e800>;
		//	snps,low_credit = <0xffc18000>;
		//	snps,priority = <0x2>;
		//};
	};

	ethernet: stmmac@f8103000 {
		compatible = "snps,dwmac-3.70a";
		reg = <0x00 0xf8103000 0x00 0x2000>;
		interrupt-parent = <&gic>;
		interrupts = <GIC_SPI 19 IRQ_TYPE_LEVEL_HIGH>,
			     <GIC_SPI 21 IRQ_TYPE_LEVEL_HIGH>,
			     <GIC_SPI 58 IRQ_TYPE_LEVEL_HIGH>;
		interrupt-names = "macirq", "eth_wake_irq", "eth_lpi";
		wakeup-source;
		clocks = <&clkc GMAC>, <&clkc RBUS>;
		clock-names = "stmmaceth", "ptp_ref";
		clock_in_out = "output";
		resets = <&rstc RST_GMAC>, <&rstc RST_PD_GMAC>;
		reset-names = "rstc_gmac", "rstc_pd_gmac";

		snps,axi-config = <&stmmac_axi_setup>;
		snps,mtl-rx-config = <&mtl_rx_setup>;
		snps,mtl-tx-config = <&mtl_tx_setup>;
		nvmem-cell-names = "mac-address";
		nvmem-cells = <&mac_addr 0>;
	};

	otp0: otp@f8802380 {
		compatible = "sunplus,sp7350-ocotp";
		reg = <0x00 0xf8802380 0x00 0x60>, <0x00 0xf8802400 0x00 0x80>, <0x00 0xf8802480 0x00 0x18>;
		reg-names = "hb_gpio", "otprx", "otp_key";
		clocks = <&clkc OTPRX>;
		resets = <&rstc RST_OTPRX>;
		nvmem-layout {
			compatible = "fixed-layout";
			#address-cells = <1>;
			#size-cells = <1>;
			therm_calib: therm_calib@9 {
				reg = <0x9 0x3>;
			};
			mac_addr: mac-address@16 {
				#nvmem-cell-cells = <1>;
				compatible = "mac-base";
				reg = <0x16 0x6>;
			};
			disc_vol: disc_vol@2d {
				reg = <0x2d 0x1>;
			};
		};
	};

	mmc0: mmc@f8003b00 {
		compatible = "sunplus,sp7350-emmc";
		reg = <0x0 0xf8003b00 0x0 0x180>, <0x0 0xf8803280 0x0 0x80>, <0x0 0xf8803354 0x0 0x0C>;
		interrupt-parent = <&gic>;
		interrupts = <GIC_SPI 17 IRQ_TYPE_LEVEL_HIGH>;
		clocks = <&clkc CARD_CTL0>;
		resets = <&rstc RST_CARD_CTL0>;
		pinctrl-names = "default";
		pinctrl-0 = <&emmc_pins>;
		bus-width = <8>;
		non-removable;
		disable-wp;
		cap-mmc-highspeed;
		no-sdio;
		no-sd;
	};

	axi: axi@f8012b80 {
		compatible = "sunplus,sp7350-axi";
		reg = <0x0 0xf8012b80 0x0 0x80>, <0x0 0xf8012c00 0x0 0x80>, <0x0 0xf8012c80 0x0 0x80>,
		      <0x0 0xf8012d00 0x0 0x80>, <0x0 0xf8012d80 0x0 0x80>, <0x0 0xf8012e00 0x0 0x80>,
		      <0x0 0xf8012e80 0x0 0x80>, <0x0 0xf8012f00 0x0 0x80>, <0x0 0xf8012f80 0x0 0x80>,
		      <0x0 0xf8013000 0x0 0x80>, <0x0 0xf8013080 0x0 0x80>, <0x0 0xf8013100 0x0 0x80>,
		      <0x0 0xf8013180 0x0 0x80>, <0x0 0xf8013200 0x0 0x80>, <0x0 0xf8013280 0x0 0x80>,
		      <0x0 0xf8013300 0x0 0x80>, <0x0 0xf8013380 0x0 0x80>, <0x0 0xf8013400 0x0 0x80>,
		      <0x0 0xf8013480 0x0 0x80>, <0x0 0xf8013500 0x0 0x80>, <0x0 0xf8013580 0x0 0x80>,
		      <0x0 0xf8013600 0x0 0x80>, <0x0 0xf8013680 0x0 0x80>, <0x0 0xf8013700 0x0 0x80>,
		      <0x0 0xf8013780 0x0 0x80>, <0x0 0xf8013800 0x0 0x80>, <0x0 0xf8013880 0x0 0x80>,
		      <0x0 0xf8013900 0x0 0x80>, <0x0 0xf8013980 0x0 0x80>, <0x0 0xf8013a00 0x0 0x80>,
			  <0x0 0xf8013a80 0x0 0x80>, <0x0 0xf8013b00 0x0 0x80>, <0x0 0xf8013b80 0x0 0x80>;
		reg-names = "axi_mon", "axi_0", "axi_1",
			    "axi_2", "axi_3", "axi_4",
			    "axi_5", "axi_6", "axi_7",
			    "axi_8", "axi_9", "axi_10",
			    "axi_11", "axi_12", "axi_13",
			    "axi_14", "axi_15", "axi_16",
			    "axi_17", "axi_18", "axi_19",
			    "axi_20", "axi_21", "axi_22",
			    "axi_23", "axi_24", "axi_25",
			    "axi_26", "axi_27", "axi_28",
				"axi_29", "axi_30", "axi_31";
		interrupt-parent = <&gic>;
		interrupts = <GIC_SPI 49 IRQ_TYPE_LEVEL_HIGH>;
	};

	nic: nic@f8012b80 {
		compatible = "sunplus,sp7350-nic";
		reg = <0x0 0xf815a000 0x0 0x2E8>, <0x0 0xf815b000 0x0 0x33c>, <0x0 0xf815c000 0x0 0x4fc>;
		reg-names = "nic_main", "nic_pai", "nic_paii";
	};

	mmc1: mmc@f8003e80 {
		compatible = "sunplus,sp7350-sd";
		reg = <0x0 0xf8003e80 0x0 0x180>;
		interrupt-parent = <&gic>;
		interrupts = <GIC_SPI 16 IRQ_TYPE_LEVEL_HIGH>;
		clocks = <&clkc CARD_CTL1>;
		resets = <&rstc RST_CARD_CTL1>;
		bus-width = <4>;
	};

	sdio: sdio@f8008400 {
		compatible = "sunplus,sp7350-1v8-sdio";
		reg = < 0x0 0xf8008400 0x0 0x180>;
		interrupt-parent = <&gic>;
		interrupts = <GIC_SPI 15 IRQ_TYPE_LEVEL_HIGH>;
		clocks = <&clkc CARD_CTL2>;
		resets = <&rstc RST_CARD_CTL2>;
		bus-width = <4>;
	};

	sp_uphy0: uphy@f8004a80 {
		compatible = "sunplus,sp7350-usb2-phy";
		clocks = <&clkc UPHY0>;
		resets = <&rstc RST_UPHY0>;
		reg = <0x0 0xf8004a80 0x0 0x80>, <0x0 0xf8800200 0x0 0x80>;
		reg-names = "phy", "moon4";
		interrupt-parent = <&gic>;
		interrupts = <GIC_SPI 148 IRQ_TYPE_LEVEL_HIGH>;
		nvmem-cell-names = "disc_vol";
		nvmem-cells = <&disc_vol>;
		#phy-cells = <0>;
		sunplus,disc-vol-addr-off = <0>;
	};

	ehci0: usb@f8102100 {
		compatible = "sunplus,sp7350-usb-ehci";
		clocks = <&clkc USBC0>;
		resets = <&rstc RST_USBC0>;
		reg = <0x00 0xf8102100 0x00 0x68>;
		interrupt-parent = <&gic>;
		interrupts = <GIC_SPI 183 IRQ_TYPE_LEVEL_HIGH>;
		phys = <&sp_uphy0>;
		phy-names = "uphy";
	};

	ohci0: usb@f8102080 {
		compatible = "sunplus,sp7350-usb-ohci";
		clocks = <&clkc USBC0>;
		resets = <&rstc RST_USBC0>;
		reg = <0x00 0xf8102080 0x00 0x68>, <0x00 0xf8800000 0x00 0x80>;
		interrupt-parent = <&gic>;
		interrupts = <GIC_SPI 184 IRQ_TYPE_LEVEL_HIGH>;
		phys = <&sp_uphy0>;
		phy-names = "uphy";
	};

	udc0: usb@f8102800 {
		compatible = "sunplus,sp7350-usb-udc";
		clocks = <&clkc USBC0>;
		resets = <&rstc RST_USBC0>;
		reg = <0x0 0xf8102800 0x0 0x288>, <0x0 0xf8800200 0x0 0x80>, <0x0 0xf8800000 0x0 0x80>,
		      <0x0 0xf8800080 0x0 0x80>, <0x0 0xf8800100 0x0 0x80>, <0x0 0xf8004a80 0x0 0x80>,
		      <0x0 0xf8802380 0x0 0x80>;
		interrupt-parent = <&gic>;
		interrupts = <GIC_SPI 182 IRQ_TYPE_LEVEL_HIGH>;
		phys = <&sp_uphy0>;
		phy-names = "uphy";
	};

	otg: usb@f8102400 {
		compatible = "sunplus,sp7350-usb-otg";
		clocks = <&clkc USBC0>;
		resets = <&rstc RST_USBC0>;
		reg = <0x0 0xf8102400 0x0 0x80>;
		interrupt-parent = <&gic>;
		interrupts = <GIC_SPI 181 IRQ_TYPE_LEVEL_HIGH>;
		phys = <&sp_uphy0>;
		phy-names = "uphy";
	};

	extcon_dwc3drd: extcon_usb3 {
		compatible = "linux,extcon-usb-gpio";
		reg = <0x0 0xf8004a80 0x0 0x80>;
		clocks = <&clkc UPHY0>;
	};

	usb3drd0: usb3drd0{
		compatible = "sunplus,dwcusb3";
		#address-cells = <2>;
		#size-cells = <2>;
		ranges;
		clocks = <&clkc USB30C0>, <&clkc USB30C0>, <&clkc USB30C0>;
		clock-names = "ref","bus_early","suspend";
		resets = <&rstc RST_USB30C0>;

		usbdrd_dwc3_0: dwc3@f80a1000 {
			compatible = "synopsys,dwc3";
			reg = <0x0 0xf80a1000 0x0 0xe000>;
			interrupt-parent = <&gic>;
			interrupts = <GIC_SPI 179 IRQ_TYPE_LEVEL_HIGH>;
			snps,dis_u2_susphy_quirk;
			phy_type = "utmi_wide";
			extcon = <&extcon_dwc3drd>;
			phys = <&u3phy0>, <&u3phy0>;
			phy-names = "usb3-phy", "usb2-phy";
		};
	};

	spdwc3: spdwc3@f80a1000 {
		compatible = "sunplus,dwc3";
		reg = <0x0 0xf80a1000 0x0 0xe000>;
	};

	u3phy0: uphy@f80bd000 {
		compatible = "sunplus,usb3-phy";
		reg = <0x0 0xf80bd000 0x0 0x80>, <0x0 0xf80a1430 0x0 0x80>, <0x0 0xf80ad700 0x0 0x80>;
		interrupt-parent = <&gic>;
		interrupts = <GIC_SPI 191 IRQ_TYPE_LEVEL_HIGH>;
		clocks = <&clkc U3PHY0>, <&clkc USB30C0>;
		clock-names = "clkc_u3phy", "clkc_u3";
		resets = <&rstc RST_U3PHY0>;
		reset-names = "rstc_u3phy";
		#phy-cells = <0>;
	};

	audio: audio@f8800480 {
		compatible = "sunplus,audio";
		reg = <0x00 0xf8800480 0x00 0x700>;
		reg-names = "audio";
		interrupt-parent = <&gic>;
		interrupts = <GIC_SPI 101 IRQ_TYPE_LEVEL_HIGH>;
		clocks = <&clkc AUD>;
		clock-names = "aud";
		resets = <&rstc RST_AUD>;
	};

	sp_spinor0: spinor@f8000b00 {
		compatible = "sunplus,sp7350-spi-nor";
		reg = <0x0 0xf8000b00 0x0 0x80>;
		interrupt-parent = <&gic>;
		interrupts = <GIC_SPI 18 IRQ_TYPE_LEVEL_HIGH>;
		clocks = <&clkc SPIFL>;
		resets = <&rstc RST_SPIFL>;
	};

	spinand0: spinand@f8002b80 {
		compatible = "sunplus,sp7350-spi-nand";
		reg = <0x0 0xf8002b80 0x0 0x60>, <0x0 0xf8101000 0x0 0x30>;
		reg-names = "nand", "bch";
		interrupt-parent = <&gic>;
		interrupts = <GIC_SPI 23 IRQ_TYPE_LEVEL_HIGH>, <GIC_SPI 24 IRQ_TYPE_LEVEL_HIGH>;
		interrupt-names = "int_nand", "int_bch";
		clocks = <&clkc SPIND>, <&clkc BCH>;
		clock-names = "clk_nand", "clk_bch";
		resets = <&rstc RST_SPIND>, <&rstc RST_BCH>;
		reset-names = "rst_nand", "rst_bch";
	};

	paranand0: paranand@f8120000 {
		compatible = "sunplus,sp7350-para-nand";
		reg = <0x0 0xf8120000 0x0 0x3000>, <0x0 0xfb000000 0x0 0x4000000>;
		interrupt-parent = <&gic>;
		interrupts = <GIC_SPI 71 IRQ_TYPE_LEVEL_HIGH>;
		clocks = <&clkc PNAND>;
		resets = <&rstc RST_PNAND>;
		dmas = <&dmac 2>;
		dma-names = "rxtx";
	};

	video_codec: video_codec {
		compatible = "sunplus,sp7350-hantro-codec";
		clocks = <&clkc VIDEO_CODEC>;
		clock-names = "clk_vcodec";
		resets = <&rstc RST_VIDEO_CODEC>, <&rstc RST_VCL>, <&rstc RST_VCL0>, <&rstc RST_VCL1>, <&rstc RST_VCL2>, <&rstc RST_VCL3>, <&rstc RST_VCL4>, <&rstc RST_VCL5>;
		reset-names = "rstc_vcodec", "rstc_vcl", "rstc_vcl0", "rstc_vcl1", "rstc_vcl2", "rstc_vcl3", "rstc_vcl4", "rstc_vcl5";
	};

	video_codec_dec: hantro_vc8000d@f8168000 {
		compatible = "sunplus,sp7350-hantro-vc8000d";
		reg = <0x00 0xf8168000 0x00 0x1d8>;
		interrupt-parent = <&gic>;
		interrupts = <GIC_SPI 167 IRQ_TYPE_LEVEL_HIGH>;
		clocks = <&clkc VCD>;
		clock-names = "clk_vc8000d";
		resets = <&rstc RST_VCD>;
		reset-names = "rstc_vc8000d";
	};

	video_codec_enc: hantro_vc8000e@f80ff000 {
		compatible = "sunplus,sp7350-hantro-vc8000e";
		reg = <0x00 0xf80ff000 0x00 0xfff>;
		interrupt-parent = <&gic>;
		interrupts = <GIC_SPI 77 IRQ_TYPE_LEVEL_HIGH>;
		clocks = <&clkc VCE>;
		clock-names = "clk_vc8000e";
		resets = <&rstc RST_VCE>;
		reset-names = "rstc_vc8000e";
	};

	vcodec_emem: video_codec_emem {
		compatible = "sunplus,sp7350-hantro-emem";
	};

	vcodec_dmem: video_codec_dmem {
		compatible = "sunplus,sp7350-hantro-dmem";
	};

	vcodec_v4l2_mem: video_codec_v4l2 {
		compatible = "sunplus,sp7350-hantro-vsiv4l2";
	};

	galcore: galcore@f8140000 {
		compatible = "galcore";
		reg = <0x0 0xf8140000 0x0 0x20000>, <0x0 0xf880125c 0x0 0xff>;
		reg-name = "galcore","gal_ios";
		dev_name = "galcore";
		interrupt-parent = <&gic>;
		interrupts = <GIC_SPI 165 IRQ_TYPE_LEVEL_HIGH>;
		clocks = <&clkc NPU>;
		clock-names = "clk_npu";
		clock-frequency = <900000000>;
		resets = <&rstc RST_NPU>;
		reset-names = "rstc_npu";
	};

	gdc: gdc@f8c09000 {
		compatible = "sunplus,sp7350-gdc";
		reg = <0x0 0xf8c09000 0x0 0xff>;
		interrupt-parent = <&gic>;
		interrupts = <GIC_SPI 108 IRQ_TYPE_EDGE_RISING>;
		clocks = <&clkc VCL>, <&clkc VCL5>, <&clkc VCL3>;
		clock-names = "sys", "axi", "apb";
		resets = <&rstc RST_VCL>, <&rstc RST_VCL5>, <&rstc RST_VCL3>;
		reset-names = "sys", "axi", "apb";
		sunplus,max-config-size = <0x100000>;
		sunplus,devnode-number = <96>;
	};

	dummymaster: dm@f8000700 {
		compatible = "sunplus,sp7350-dm-test";
		reg = <0x0 0xf8800100 0x0 0x80>, <0x0 0xf8000700 0x0 0x80>,
			<0x0 0xf800a880 0x0 0x80>; /* G14 G337 */
		clocks = <&clkc DUMMY_MASTER0>, <&clkc DUMMY_MASTER1>;
		clock-names = "clk_dm0", "clk_dm1";
		resets = <&rstc DUMMY_MASTER0>, <&rstc DUMMY_MASTER1>;
		reset-names = "rstc_dm0", "rstc_dm1";
	};

	watchdog: watchdog@f800061c {
		compatible = "sunplus,sp7350-wdt";
		reg = <0x00 0xf800061c 0x00 0x08>, <0x00 0xf800066c 0x00 0x08>,
			<0x00 0xf8800258 0x00 0x04>, <0x00 0xf800060c 0x00 0x04>;
		interrupt-parent = <&gic>;
		interrupts = <GIC_SPI 113 IRQ_TYPE_LEVEL_HIGH>;
		clocks = <&clkc STC_AV3>;
		resets = <&rstc RST_STC_AV3>;
	};

	stc: stc@f8800b80 {
		compatible = "sunplus,sp7350-stc";
		reg = <0x00 0xf8800b80 0x00 0x14>;
		clocks = <&clkc SYSAO>;
		clock-names = "clk_sys";

		#address-cells = <2>;
		#size-cells = <2>;
		ranges;

		stc_timer0: timer0@f8800ba4 {
			compatible = "sunplus,sp7350-timer";
			reg = <0x0 0xf8800ba4 0x0 0xc>;
			interrupt-parent = <&gic>;
			interrupts = <GIC_SPI 129 IRQ_TYPE_EDGE_RISING>;
		};
		stc_timer1: timer1@f8800bb0 {
			compatible = "sunplus,sp7350-timer";
			reg = <0x0 0xf8800bb0 0x0 0xc>;
			interrupt-parent = <&gic>;
			interrupts = <GIC_SPI 130 IRQ_TYPE_EDGE_RISING>;
		};
		stc_timer2: timer2@f8800bbc {
			compatible = "sunplus,sp7350-timer";
			reg = <0x0 0xf8800bbc 0x0 0xc>;
			interrupt-parent = <&gic>;
			interrupts = <GIC_SPI 131 IRQ_TYPE_EDGE_RISING>;
		};
		stc_timer3: timer3@f8800bc8 {
			compatible = "sunplus,sp7350-timer";
			reg = <0x0 0xf8800bc8 0x0 0x14>;
			interrupt-parent = <&gic>;
			interrupts = <GIC_SPI 132 IRQ_TYPE_EDGE_RISING>;
		};
	};

	stc_av0: stc_av0@f8800c00 {
		compatible = "sunplus,sp7350-stc";
		reg = <0x00 0xf8800c00 0x00 0x14>;
		clocks = <&clkc SYSAO>;
		clock-names = "clk_sys";

		#address-cells = <2>;
		#size-cells = <2>;
		ranges;

		stc_av0_timer0: timer0@f8800c24 {
			compatible = "sunplus,sp7350-timer";
			reg = <0x0 0xf8800c24 0x0 0xc>;
			interrupt-parent = <&gic>;
			interrupts = <GIC_SPI 133 IRQ_TYPE_EDGE_RISING>;
		};
		stc_av0_timer1: timer1@f8800c30 {
			compatible = "sunplus,sp7350-timer";
			reg = <0x0 0xf8800c30 0x0 0xc>;
			interrupt-parent = <&gic>;
			interrupts = <GIC_SPI 134 IRQ_TYPE_EDGE_RISING>;
		};
		stc_av0_timer2: timer2@f8800c3c {
			compatible = "sunplus,sp7350-timer";
			reg = <0x0 0xf8800c3c 0x0 0xc>;
			interrupt-parent = <&gic>;
			interrupts = <GIC_SPI 135 IRQ_TYPE_EDGE_RISING>;
		};
		stc_av0_timer3: timer3@f8800c48 {
			compatible = "sunplus,sp7350-timer";
			reg = <0x0 0xf8800c48 0x0 0x14>;
			interrupt-parent = <&gic>;
			interrupts = <GIC_SPI 136 IRQ_TYPE_EDGE_RISING>;
		};
	};

	stc_av1: stc_av1@f8800c80 {
		compatible = "sunplus,sp7350-stc";
		reg = <0x00 0xf8800c80 0x00 0x14>;
		clocks = <&clkc SYSAO>;
		clock-names = "clk_sys";

		#address-cells = <2>;
		#size-cells = <2>;
		ranges;

		stc_av1_timer0: timer0@f8800ca4 {
			compatible = "sunplus,sp7350-timer";
			reg = <0x0 0xf8800ca4 0x0 0xc>;
			interrupt-parent = <&gic>;
			interrupts = <GIC_SPI 137 IRQ_TYPE_EDGE_RISING>;
		};
		stc_av1_timer1: timer1@f8800cb0 {
			compatible = "sunplus,sp7350-timer";
			reg = <0x0 0xf8800cb0 0x0 0xc>;
			interrupt-parent = <&gic>;
			interrupts = <GIC_SPI 138 IRQ_TYPE_EDGE_RISING>;
		};
		stc_av1_timer2: timer2@f8800cbc {
			compatible = "sunplus,sp7350-timer";
			reg = <0x0 0xf8800cbc 0x0 0xc>;
			interrupt-parent = <&gic>;
			interrupts = <GIC_SPI 139 IRQ_TYPE_EDGE_RISING>;
		};
		stc_av1_timer3: timer3@f8800cc8 {
			compatible = "sunplus,sp7350-timer";
			reg = <0x0 0xf8800cc8 0x0 0x14>;
			interrupt-parent = <&gic>;
			interrupts = <GIC_SPI 140 IRQ_TYPE_EDGE_RISING>;
		};
	};

	stc_av2: stc_av2@f8800d00 {
		compatible = "sunplus,sp7350-stc";
		reg = <0x00 0xf8800d00 0x00 0x14>;
		clocks = <&clkc SYSAO>;
		clock-names = "clk_sys";

		#address-cells = <2>;
		#size-cells = <2>;
		ranges;

		stc_av2_timer0: timer0@f8800d24 {
			compatible = "sunplus,sp7350-timer";
			reg = <0x0 0xf8800d24 0x0 0xc>;
			interrupt-parent = <&gic>;
			interrupts = <GIC_SPI 142 IRQ_TYPE_EDGE_RISING>;
		};
		stc_av2_timer1: timer1@f8800d30 {
			compatible = "sunplus,sp7350-timer";
			reg = <0x0 0xf8800d30 0x0 0xc>;
			interrupt-parent = <&gic>;
			interrupts = <GIC_SPI 143 IRQ_TYPE_EDGE_RISING>;
		};
		stc_av2_timer2: timer2@f8800d3c {
			compatible = "sunplus,sp7350-timer";
			reg = <0x0 0xf8800d3c 0x0 0xc>;
			interrupt-parent = <&gic>;
			interrupts = <GIC_SPI 144 IRQ_TYPE_EDGE_RISING>;
		};
		stc_av2_timer3: timer3@f8800d48 {
			compatible = "sunplus,sp7350-timer";
			reg = <0x0 0xf8800d48 0x0 0x14>;
			interrupt-parent = <&gic>;
			interrupts = <GIC_SPI 145 IRQ_TYPE_EDGE_RISING>;
		};
	};

	stc_av4: stc_av4@f8801300 {
		compatible = "sunplus,sp7350-stc";
		reg = <0x00 0xf8801300 0x00 0x14>;
		clocks = <&clkc SYSAO>;
		clock-names = "clk_sys";

		#address-cells = <2>;
		#size-cells = <2>;
		ranges;

		stc_av4_timer0: timer0@f8801324 {
			compatible = "sunplus,sp7350-timer";
			reg = <0x0 0xf8801324 0x0 0xc>;
			interrupt-parent = <&gic>;
			interrupts = <GIC_SPI 186 IRQ_TYPE_EDGE_RISING>;
		};
		stc_av4_timer1: timer1@f8801330 {
			compatible = "sunplus,sp7350-timer";
			reg = <0x0 0xf8801330 0x0 0xc>;
			interrupt-parent = <&gic>;
			interrupts = <GIC_SPI 187 IRQ_TYPE_EDGE_RISING>;
		};
		stc_av4_timer2: timer2@f880133c {
			compatible = "sunplus,sp7350-timer";
			reg = <0x0 0xf880133c 0x0 0xc>;
			interrupt-parent = <&gic>;
			interrupts = <GIC_SPI 188 IRQ_TYPE_EDGE_RISING>;
		};
		stc_av4_timer3: timer3@f8801348 {
			compatible = "sunplus,sp7350-timer";
			reg = <0x0 0xf8801348 0x0 0x14>;
			interrupt-parent = <&gic>;
			interrupts = <GIC_SPI 189 IRQ_TYPE_EDGE_RISING>;
		};
	};

	timer_test: timer_test@f8000580 {
		compatible = "sunplus,sp7350-timer-test";
		reg =
			<0x00 0xf8000580 0x00 0x80>, <0x00 0xf8000600 0x00 0x80>,
			<0x00 0xf8800b80 0x00 0x80>, <0x00 0xf8800c00 0x00 0x80>,
			<0x00 0xf8800c80 0x00 0x80>, <0x00 0xf8800d00 0x00 0x80>,
			<0x00 0xf8801300 0x00 0x80>;
		reg-names =
			"stc_timestamp", "stc_av3",
			"stc", "stc_av0",
			"stc_av1", "stc_av2",
			"stc_av4";
		interrupt-parent = <&gic>;
		interrupts =
			<GIC_SPI 52 IRQ_TYPE_EDGE_RISING>,/* STC_TIMESTAMP_INTERRUPT_TIMER0 */
			<GIC_SPI 53 IRQ_TYPE_EDGE_RISING>,/* STC_TIMESTAMP_INTERRUPT_TIMER1 */
			<GIC_SPI 54 IRQ_TYPE_EDGE_RISING>,/* STC_TIMESTAMP_INTERRUPT_TIMER2B */
			<GIC_SPI 55 IRQ_TYPE_EDGE_RISING>,/* STC_TIMESTAMP_INTERRUPT_TIMER3B */
			<GIC_SPI 114 IRQ_TYPE_EDGE_RISING>,/* STC_AV3_INTERRUPT_TIMER0 */
			<GIC_SPI 115 IRQ_TYPE_EDGE_RISING>,/* STC_AV3_INTERRUPT_TIMER1 */
			<GIC_SPI 116 IRQ_TYPE_EDGE_RISING>,/* STC_AV3_INTERRUPT_TIMER2B */
			<GIC_SPI 117 IRQ_TYPE_EDGE_RISING>,/* STC_AV3_INTERRUPT_TIMER3B */
			<GIC_SPI 129 IRQ_TYPE_EDGE_RISING>,/* STC_INTERRUPT_TIMER0 */
			<GIC_SPI 130 IRQ_TYPE_EDGE_RISING>,/* STC_INTERRUPT_TIMER1 */
			<GIC_SPI 131 IRQ_TYPE_EDGE_RISING>,/* STC_INTERRUPT_TIMER2B */
			<GIC_SPI 132 IRQ_TYPE_EDGE_RISING>,/* STC_INTERRUPT_TIMER3B */
			<GIC_SPI 133 IRQ_TYPE_EDGE_RISING>,/* STC_AV0_INTERRUPT_TIMER0 */
			<GIC_SPI 134 IRQ_TYPE_EDGE_RISING>,/* STC_AV0_INTERRUPT_TIMER1 */
			<GIC_SPI 135 IRQ_TYPE_EDGE_RISING>,/* STC_AV0_INTERRUPT_TIMER2B */
			<GIC_SPI 136 IRQ_TYPE_EDGE_RISING>,/* STC_AV0_INTERRUPT_TIMER3B */
			<GIC_SPI 137 IRQ_TYPE_EDGE_RISING>,/* STC_AV1_INTERRUPT_TIMER0 */
			<GIC_SPI 138 IRQ_TYPE_EDGE_RISING>,/* STC_AV1_INTERRUPT_TIMER1 */
			<GIC_SPI 139 IRQ_TYPE_EDGE_RISING>,/* STC_AV1_INTERRUPT_TIMER2B */
			<GIC_SPI 140 IRQ_TYPE_EDGE_RISING>,/* STC_AV1_INTERRUPT_TIMER3B */
			<GIC_SPI 142 IRQ_TYPE_EDGE_RISING>,/* STC_AV2_INTERRUPT_TIMER0 */
			<GIC_SPI 143 IRQ_TYPE_EDGE_RISING>,/* STC_AV2_INTERRUPT_TIMER1 */
			<GIC_SPI 144 IRQ_TYPE_EDGE_RISING>,/* STC_AV2_INTERRUPT_TIMER2B */
			<GIC_SPI 145 IRQ_TYPE_EDGE_RISING>,/* STC_AV2_INTERRUPT_TIMER3B */
			<GIC_SPI 186 IRQ_TYPE_EDGE_RISING>,/* STC_AV4_INTERRUPT_TIMER0 */
			<GIC_SPI 187 IRQ_TYPE_EDGE_RISING>,/* STC_AV4_INTERRUPT_TIMER1 */
			<GIC_SPI 188 IRQ_TYPE_EDGE_RISING>,/* STC_AV4_INTERRUPT_TIMER2B */
			<GIC_SPI 189 IRQ_TYPE_EDGE_RISING>;/* STC_AV4_INTERRUPT_TIMER3B */
	};

	mbox: mbox@f8008100 {
		compatible = "sunplus,sunplus-mbox";
		reg = <0x0 0xf8008100 0x0 0x60>, <0x0 0xf8008180 0x0 0x60>; /* G258 ~ G259 */
		reg-names = "mbox_0_to_2", "mbox_2_to_0";
		interrupt-parent = <&gic>;
		interrupts = <GIC_SPI 126 IRQ_TYPE_LEVEL_HIGH>; /* CPU2_TO_0_INT */
		clocks = <&clkc MAILBOX>;
		#mbox-cells = <1>;
	};

	pctl: pinctrl@f8800080 {
		compatible = "sunplus,sp7350-pctl";
		reg =
			<0x0 0xf8800080 0x0 0x2c>,
			<0x0 0xf8803280 0x0 0x60>,
			<0x0 0xf88032e4 0x0 0x1c>,
			<0x0 0xf8803300 0x0 0x80>,
			<0x0 0xf8803380 0x0 0x180>,
			<0x0 0xf8802f80 0x0 0x1c>;
		reg-names = "moon1", "pad_ctl_1", "first", "pad_ctl_2", "gpioxt", "gpio_ao_int";
		gpio-controller;
		#gpio-cells = <2>;
	};
};
